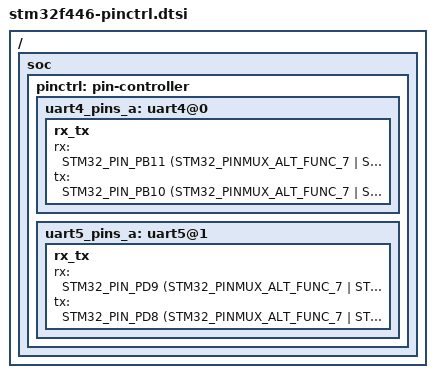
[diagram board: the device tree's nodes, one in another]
/*
 * Copyright (c) 2017 Linaro Limited
 *
 * SPDX-License-Identifier: Apache-2.0
 */

#include <dt-bindings/pinctrl/stm32-pinctrl.h>

/ {
	soc {
		pinctrl: pin-controller {
			uart4_pins_a: uart4@0 {
				rx_tx {
					rx = <STM32_PIN_PB11 (STM32_PINMUX_ALT_FUNC_7 | STM32_PUSHPULL_PULLUP)>;
					tx = <STM32_PIN_PB10 (STM32_PINMUX_ALT_FUNC_7 | STM32_PUSHPULL_PULLUP)>;
				};
			};

			uart5_pins_a: uart5@1 {
				rx_tx {
					rx = <STM32_PIN_PD9 (STM32_PINMUX_ALT_FUNC_7 | STM32_PUSHPULL_PULLUP)>;
					tx = <STM32_PIN_PD8 (STM32_PINMUX_ALT_FUNC_7 | STM32_PUSHPULL_PULLUP)>;
				};
			};
		};
	};
};
